# ATSAMRH71F20B device description
Architecture: CORTEX-M7; Family: SAMRH; Series: SAMRH71
Registers are 32-bit, read-write, no defined reset value unless marked. A register's access mark holds for its fields unless they carry their own. Offsets are from the block's base; [hi:lo] are bit positions; 'fields as' and 'values as' point back to an identical list.

## RSTC — Reset Controller
Instances: RSTC 0x40100200
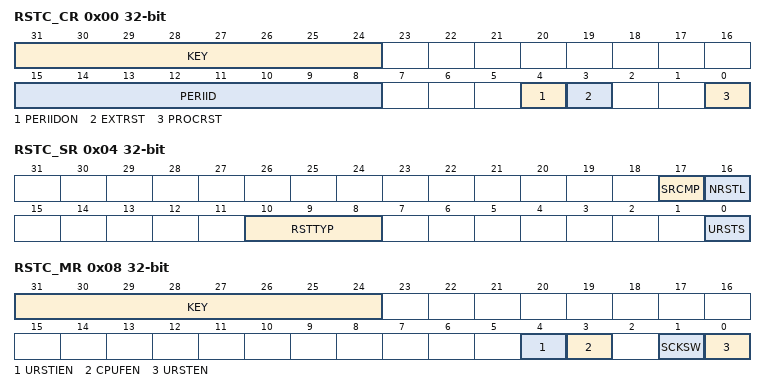
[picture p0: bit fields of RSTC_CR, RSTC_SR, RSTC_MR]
0x00 RSTC_CR wo — Control Register
  [31:24] KEY — System Reset Key
    165=PASSWD (Writing any other value in this field aborts the write operation.)
  [15:8] PERIID — Peripheral Identifier
  [4] PERIIDON — External Reset
  [3] EXTRST — External Reset
  [0] PROCRST — Processor Reset
0x04 RSTC_SR ro — Status Register
  [17] SRCMP — Software Reset Command in Progress
  [16] NRSTL — NRST Pin Level
  [10:8] RSTTYP — Reset Type
    0=GENERAL_RST (First powerup reset); 2=WDT_RST (Watchdog fault occurred); 3=SOFT_RST (Processor reset required by the software); 4=USER_RST (NRST pin detected low); 6=CPU_FAIL_RST (CPU clock failure detection occurred); 7=SLCK_XTAL_RST (32.768 kHz crystal failure detection fault occurred)
  [0] URSTS — User Reset Status
0x08 RSTC_MR — Mode Register
  [31:24] KEY — Write Access Password
    165=PASSWD (Writing any other value in this field aborts the write operation.Always reads as 0.)
  [4] URSTIEN — User Reset Interrupt Enable
  [3] CPUFEN — CPU Fail Enable
  [1] SCKSW — Slow Clock Switching
  [0] URSTEN — User Reset Enable

## RTT — Real-time Timer
Instances: RTT 0x40100230
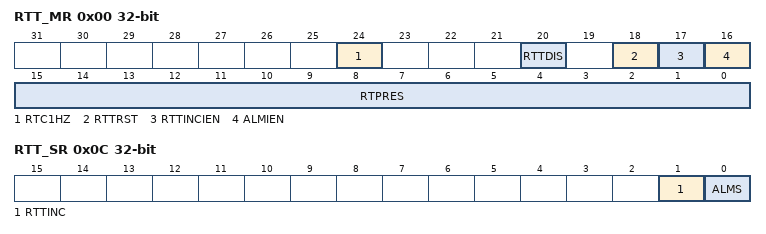
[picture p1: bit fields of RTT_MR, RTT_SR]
0x00 RTT_MR — Mode Register
  [24] RTC1HZ — Real-Time Clock 1Hz Clock Selection
  [20] RTTDIS — Real-time Timer Disable
  [18] RTTRST — Real-time Timer Restart
  [17] RTTINCIEN — Real-time Timer Increment Interrupt Enable
  [16] ALMIEN — Alarm Interrupt Enable
  [15:0] RTPRES — Real-time Timer Prescaler Value
0x04 RTT_AR — Alarm Register
  [31:0] ALMV — Alarm Value
0x08 RTT_VR ro — Value Register
  [31:0] CRTV — Current Real-time Value
0x0C RTT_SR ro — Status Register
  [1] RTTINC — Prescaler Roll-over Status (cleared on read)
  [0] ALMS — Real-time Alarm Status (cleared on read)

## SFR — Special Function Registers
Instances: SFR 0x400A0000
0x28 SFR_SECURE — Security Configuration Register
  [0] ROM — Disable Access to ROM Code
0xA0 SFR_CAN0 — CAN0 MSB Base Address 0
  [31:16] EXT_MEM_ADDR — MSB Base Address
0xA4 SFR_CAN1 — CAN0 MSB Base Address 1
  [31:16] EXT_MEM_ADDR — MSB Base Address

## SUPC — Supply Controller
Instances: SUPC 0x40100210
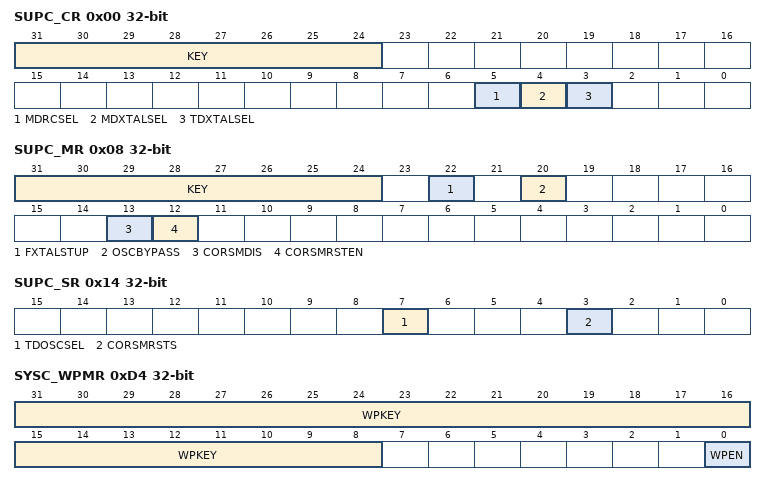
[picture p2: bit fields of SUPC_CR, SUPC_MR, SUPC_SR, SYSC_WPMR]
0x00 SUPC_CR wo — Supply Controller Control Register
  [31:24] KEY — Password
    165=PASSWD (Writing any other value in this field aborts the write operation.)
  [5] MDRCSEL — Monitoring Domain RC Oscillator Select
    0=NO_EFFECT; 1=CRYSTAL_SEL (If KEY is correct, XTALSEL switches the slow clock of the monitoring domain (MD_SLCK) on the slow RC oscillator output.)
  [4] MDXTALSEL — Monitoring Domain Crystal Oscillator Select
    0=NO_EFFECT; 1=CRYSTAL_SEL (If KEY is correct, XTALSEL switches the slow clock of the monitoring domain (MD_SLCK) on the 32.768 kHz crystal oscillator output.)
  [3] TDXTALSEL — Timing Domain Crystal Oscillator Select
    0=NO_EFFECT; 1=CRYSTAL_SEL (If KEY is correct, XTALSEL switches the slow clock of the timing domain (TD_SLCK) on the 32.768 kHz crystal oscillator output.)
0x04 SUPC_SMMR — Supply Controller Supply Monitor Mode Register
  [23] CORESMUSEL — Core Supply Monitor User Selection
0x08 SUPC_MR — Supply Controller Mode Register
  [31:24] KEY — Password Key
    values as SUPC_CR.KEY
  [22] FXTALSTUP — Fast Startup 32.768 kHz Crystal Oscillator
  [20] OSCBYPASS — Oscillator Bypass
    0=NO_EFFECT (No effect. Clock selection depends on the value of XTALSEL (SUPC_CR).); 1=BYPASS (The 32.768 kHz crystal oscillator is bypassed if XTALSEL (SUPC_CR) is set. OSCBYPASS must be set prior to setting XTALSEL.)
  [13] CORSMDIS — VDDCORE Supply Monitor Disable
    0=ENABLE (The VDDCORE supply monitor is enabled.); 1=DISABLE (The VDDCORE supply monitor is disabled.)
  [12] CORSMRSTEN — VDDCORE Supply Monitor Reset Enable
    0=NOT_ENABLE (The core reset signal vddcore_nreset is not affected when a VDDCORE supply monitor detection occurs.); 1=ENABLE (The core reset signal, vddcore_nreset is asserted when a VDDCORE supply monitor detection occurs.)
0x14 SUPC_SR ro — Supply Controller Status Register
  [7] TDOSCSEL — 32 kHz Oscillator Selection Status
    0=RC (The timing domain slow clock, TD_SLCK, is generated by the slow RC oscillator.); 1=CRYST (The timing domain slow clock, TD_SLCK, is generated by the 32.768 kHz crystal oscillator.)
  [3] CORSMRSTS — VDDCORE Supply Monitor Reset Status (cleared on read)
    0=NO (No VDDCORE Supply Monitor reset event has been detected since the last read of the SUPC_SR.); 1=PRESENT (At least one VDDCORE Supply Monitor reset event has been detected since the last read of the SUPC_SR.)
0x1C SUPC_PWR — Supply Controller Power Register
  [18] MONSELS — Monitoring Oscillator Selection Status
    0=RC (The monitoring domain slow clock, MD_SLCK, is generated by the slow RC oscillator.); 1=CRYST (The monitoring domain slow clock, MD_SLCK, is generated by the 32.768 kHz crystal oscillator.)
0xD4 SYSC_WPMR — Write Protection Mode Register
  [31:8] WPKEY — Write Protection Key.
    0x525443=PASSWD (Writing any other value in this field aborts the write operation of the WPEN bit.Always reads as 0.)
  [0] WPEN — Write Protection Enable
